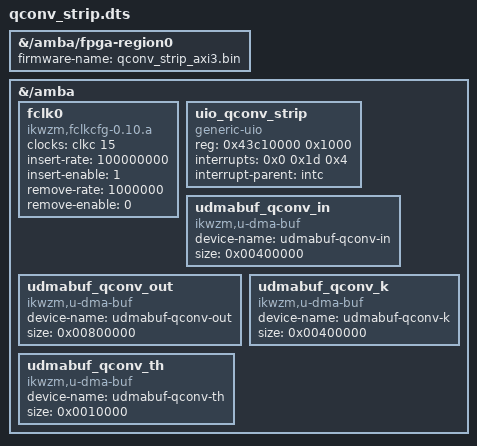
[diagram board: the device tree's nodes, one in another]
/dts-v1/; /plugin/;
/ {
	fragment@0 {
		target-path = "/amba/fpga-region0";
		__overlay__ {
			firmware-name = "qconv_strip_axi3.bin";
		};
	};

	fragment@1 {
		target-path = "/amba";
		#address-cells = <1>;
		#size-cells = <1>;
		__overlay__ {
			#address-cells = <1>;
			#size-cells = <1>;
			fclk0 {
				compatible    = "ikwzm,fclkcfg-0.10.a";
				clocks        = <&clkc 15>;
				insert-rate   = "100000000";
				insert-enable = <1>;
				remove-rate   = "1000000";
				remove-enable = <0>;
			};
			
			uio_qconv_strip {
				compatible = "generic-uio";
				reg = <0x43c10000 0x1000>;
				interrupts = <0x0 0x1d 0x4>;
				interrupt-parent = <&intc>;
	                };

			udmabuf_qconv_in {
				compatible  = "ikwzm,u-dma-buf";
				device-name = "udmabuf-qconv-in";
				size = <0x00400000>;
	                };

			udmabuf_qconv_out {
				compatible  = "ikwzm,u-dma-buf";
				device-name = "udmabuf-qconv-out";
				size = <0x00800000>;
			};
			
			udmabuf_qconv_k {
				compatible  = "ikwzm,u-dma-buf";
				device-name = "udmabuf-qconv-k";
				size = <0x00400000>;
			};

			udmabuf_qconv_th {
				compatible  = "ikwzm,u-dma-buf";
				device-name = "udmabuf-qconv-th";
				size = <0x0010000>;
			};
                };
	} ;
} ;
